# NUC1xx_registers register map
File version: 0.1
CPU: 
Registers are 32-bit, read-write, reset 0x0 unless marked. A register's access mark holds for its fields unless they carry their own. Offsets are from the block's base; [hi:lo] are bit positions; lines under a group give offsets from that group; 'fields as' and 'values as' point back to an identical list.

## CAN — Registers group
Base 0x40180000
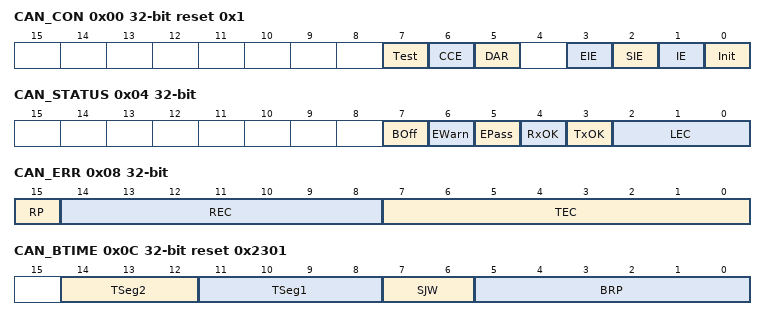
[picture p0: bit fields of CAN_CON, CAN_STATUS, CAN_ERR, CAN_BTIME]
0x00 CAN_CON reset 0x1 (reset mask 0xFFFFFFFE) — Control Register
  [7] Test — Test Mode Enable 1 = Test Mode. 0 = Normal Operation.
  [6] CCE — Configuration Change Enable 1 = Write access to the Bit Timing Register (CAN_BTIME & CAN_BRP) allowed. (while Init bit =1). 0 = No write access to the Bit Timing Register.
  [5] DAR — Disable Automatic Re-transmission 1 = Automatic Retransmission disabled. 0 = Automatic Retransmission of disturbed messages enabled.
  [3] EIE — Error Interrupt Enable 1 = Enabled - A change in the bits BOff or EWarn in the Status Register will generate an interrupt. 0 = Disabled - No Error Status Interrupt will be generated.
  [2] SIE — Status Change Interrupt Enable 1 = Enabled - An interrupt will be generated when a message transfer is successfully completed or a CAN bus error is detected. 0 = Disabled - No Status Change Interrupt will be generated.
  [1] IE — Module Interrupt Enable 1 = Enabled. 0 = Disabled.
  [0] Init — Init Initialization 1 = Initialization is started. 0 = Normal Operation.
0x04 CAN_STATUS — Status Register
  [7] BOff — Busoff Status (Read Only) 1 = The CAN module is in busoff state. 0 = The CAN module is not in busoff state.
  [6] EWarn — Error Warning Status (Read Only) 1 = At least one of the error counters in the EML has reached the error warning limit of 96. 0 = Both error counters are below the error warning limit of 96.
  [5] EPass — Error Passive (Read Only) 1 = The CAN Core is in the error passive state as defined in the CAN Specification. 0 = The CAN Core is error active.
  [4] RxOK — Received a Message Successfully 1 = A message has been successfully received since this bit was last reset by the CPU (independent of the result of acceptance filtering). 0 = No message has been successfully received since this bit was last reset by the CPU. This bit is never reset by the CAN Core.
  [3] TxOK — Transmitted a Message Successfully 1 = Since this bit was last reset by the CPU, a message has been successfully (error free and acknowledged by at least one other node) transmitted. 0 = Since this bit was reset by the CPU, no message has been successfully transmitted. This bit is never reset by the CAN Core.
  [2:0] LEC — Last Error Code (Type of the last error to occur on the CAN bus) The LEC field holds a code, which indicates the type of the last error to occur on the CAN bus. This field will be cleared to '0' when a message has been transferred (reception or transmission) without error. The unused code '7' may be written by the CPU to check for updates. Table 5-17 describes the error codes.
0x08 CAN_ERR ro — Error Counter
  [15] RP — Receive Error Passive 1 = The Receive Error Counter has reached the error passive level as defined in the CAN Specification. 0 = The Receive Error Counter is below the error passive level.
  [14:8] REC — Receive Error Counter Actual state of the Receive Error Counter. Values between 0 and 127.
  [7:0] TEC — Transmit Error Counter Actual state of the Transmit Error Counter. Values between 0 and 255.
0x0C CAN_BTIME reset 0x2301 (reset mask 0xFFFFDCFE) — Bit Timing Register
  [14:12] TSeg2 — Time Segment After sample Point 0x0-0x7: Valid values for TSeg2 are [0 ... 7]. The actual interpretation by the hardware of this value is such that one more than the value programmed here is used.
  [11:8] TSeg1 — Time Segment before the sample Point Minus Sync_seg 0x01-0x0F: valid values for TSeg1 are [1 ... 15]. The actual interpretation by the hardware of this value is such that one more than the value programmed is used.
  [7:6] SJW — (Re)Synchronization Jump Width 0x0-0x3: Valid programmed values are [0 ... 3]. The actual interpretation by the hardware of this value is such that one more than the value programmed here is used.
  [5:0] BRP — Baud Rate Prescaler 0x01-0x3F: The value by which the oscillator frequency is divided for generating the bit time quanta. The bit time is built up from a multiple of this quanta. Valid values for the Baud Rate Prescaler are [0...63]. The actual interpretation by the hardware of this value is such that one more than the value programmed here is used.
0x10 CAN_IIDR ro — Interrupt Identifier Register
  [15:0] IntId — Interrupt Identifier (Indicates the source of the interrupt. Ref. Table 5-18) If several interrupts are pending, the CAN Interrupt Register will point to the pending interrupt with the highest priority, disregarding their chronological order. An interrupt remains pending until the application software has cleared it. If IntId is different from 0x0000 and IE is set, the IRQ interrupt signal to the EIC is active. The interrupt remains active until IntId is back to value 0x0000 (the cause of the interrupt is reset) or until IE is reset. The Status Interrupt has the highest priority. Among the message interrupts, the Message Object' s interrupt priority decreases with increasing message number. A message interrupt is cleared by clearing the Message Object's IntPnd bit. The Status Interrupt is cleared by reading the Status Register.
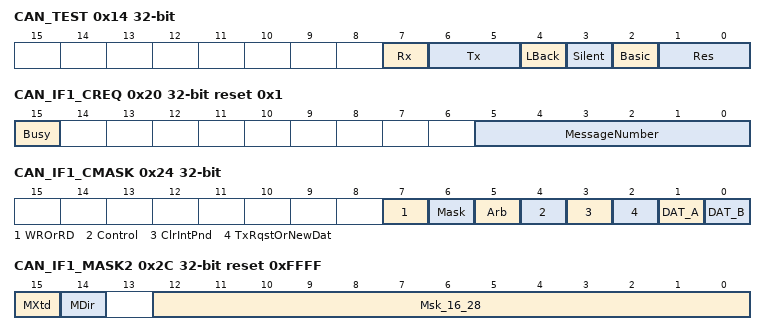
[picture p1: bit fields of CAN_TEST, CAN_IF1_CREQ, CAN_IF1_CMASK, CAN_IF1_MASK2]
0x14 CAN_TEST — Test Register
  [7] Rx — Monitors the actual value of CAN_RX Pin (Read Only) 1 = The CAN bus is recessive (CAN_RX = '1'). 0 = The CAN bus is dominant (CAN_RX = '0').
  [6:5] Tx — Tx[1:0]: Control of CAN_TX pin 00 = Reset value, CAN_TX is controlled by the CAN Core 01 = Sample Point can be monitored at CAN_TX pin 10 = CAN_TX pin drives a dominant ('0') value. 11 = CAN_TX pin drives a recessive ('1') value.
  [4] LBack — Loop Back Mode 1 = Loop Back Mode is enabled. 0 = Loop Back Mode is disabled.
  [3] Silent — Silent Mode 1 = The module is in Silent Mode. 0 = Normal operation.
  [2] Basic — Basic Mode 1= IF1 Registers used as Tx Buffer, IF2 Registers used as Rx Buffer. 0 = Basic Mode disabled.
  [1:0] Res — Reserved There are reserved bits. These bits are always read as '0' and must always be written with '0'.
0x18 CAN_BRPE — BRP Extension Register
  [3:0] BRPE — BRPE: Baud Rate Prescaler Extension 0x00-0x0F: By programming BRPE, the Baud Rate Prescaler can be extended to values up to 1023. The actual interpretation by the hardware is that one more than the value programmed by BRPE (MSBs) and BTIME (LSBs) is used.
0x20 CAN_IF1_CREQ reset 0x1 (reset mask 0xFFFFFFFE) — IF1 Command Request Register
  [15] Busy — Busy Flag 1 = Writing to the IF1 Command Request Register is in progress. This bit can only be read by the software. 0 = Read/write action has finished.
  [5:0] MessageNumber — Message Number 0x01-0x20: Valid Message Number, the Message Object in the Message RAM is selected for data transfer. 0x00: Not a valid Message Number, interpreted as 0x20. 0x21-0x3F: Not a valid Message Number, interpreted as 0x01-0x1F.
0x24 CAN_IF1_CMASK — IF1 Command Mask Registers
  [7] WROrRD — Write / Read 1 = Write: Transfer data from the selected Message Buffer Registers to the Message Object addressed by the Command Request Register. 0 = Read: Transfer data from the Message Object addressed by the Command Request Register into the selected Message Buffer Registers.
  [6] Mask — Access Mask Bits Direction = Write 1 = Transfer Identifier Mask + MDir + MXtd to Message Object. 0: = Mask bits unchanged. Direction = Read 1 = Transfer Identifier Mask + MDir + MXtd to IF1 Message Buffer Register. 0 = Mask bits unchanged.
  [5] Arb — Access Arbitration Bits Direction = Write 1 = Transfer Identifier + Dir + Xtd + MsgVal to Message Object 0 = Arbitration bits unchanged. Direction = Read 1 = Transfer Identifier + Dir + Xtd + MsgVal to IF1 Message Buffer Register. 0 = Arbitration bits unchanged.
  [4] Control — Control Access Control Bits Direction = Write 1 = Transfer Control Bits to Message Object. 0 = Control Bits unchanged Direction = Read 1 = Transfer Control Bits to IF1 Message Buffer Register. 0 = Control Bits unchanged.
  [3] ClrIntPnd — Clear Interrupt Pending Bit Direction = Write When writing to a Message Object, this bit is ignored. Direction = Read 1 = Clear IntPnd bit in the Message Object. 0 = IntPnd bit remains unchanged.
  [2] TxRqstOrNewDat — Access Transmission Request Bit when Direction = Write 1 = Set TxRqst bit. 0 = TxRqst bit unchanged. Note: If a transmission is requested by programming bit TxRqst/NewDat in the IF1 Command Mask Register, bit TxRqst in the IF2 Message Control Register will be ignored. Access New Data Bit when Direction = Read 1 = Clear NewDat bit in the Message Object 0 = NewDat bit remains unchanged. Note : A read access to a Message Object can be combined with the reset of the control bits IntPnd and NewDat. The values of these bits transferred to the IF1 Message Control Register always reflect the status before resetting these bits.
  [1] DAT_A — Access Data Bytes [3:0] Direction = Write 1 = Transfer Data Bytes [3:0] to Message Object 0 = Data Bytes [3:0] unchanged. Direction = Read 1 = Transfer Data Bytes [3:0] to IF1 Message Buffer Register. 0 = Data Bytes [3:0] unchanged.
  [0] DAT_B — Access Data Bytes [7:4] Direction = Write 1 = Transfer Data Bytes [7:4] to Message Object. 0 = Data Bytes [7:4] unchanged. Direction = Read 1 = Transfer Data Bytes [7:4] to IF1 Message Buffer Register. 0 = Data Bytes [7:4] unchanged.
0x28 CAN_IF1_MASK1 reset 0xFFFF (reset mask 0xFFFF0000) — IF1 Mask 1 Register
  [15:0] Msk_0_15 — Identifier Mask 15-0 1 = The corresponding identifier bit is used for acceptance filtering. 0 = The corresponding bit in the identifier of the message object cannot inhibit the match in the acceptance filtering.
0x2C CAN_IF1_MASK2 reset 0xFFFF (reset mask 0xFFFF0000) — IF1 Mask 2 Register
  [15] MXtd — Mask Extended Identifier 1 = The extended identifier bit (IDE) is used for acceptance filtering. 0 = The extended identifier bit (IDE) has no effect on the acceptance filtering. Note: When 11-bit ("standard") Identifiers are used for a Message Object, the identifiers of received Data Frames are written into bits ID28 to ID18. For acceptance filtering, only these bits together with mask bits Msk28 to Msk18 are considered.
  [14] MDir — Mask Message Direction 1 = The message direction bit (Dir) is used for acceptance filtering. 0 = The message direction bit (Dir) has no effect on the acceptance filtering.
  [12:0] Msk_16_28 — Identifier Mask 28-16 1 = The corresponding identifier bit is used for acceptance filtering. 0 = The corresponding bit in the identifier of the message object cannot inhibit the match in the acceptance filtering.
0x30 CAN_IF1_ARB1 — IF1 Arbitration 1 Register
  [15:0] ID_0_15 — Message Identifier 15-0 ID28 - ID0, 29-bit Identifier ("Extended Frame"). ID28 - ID18, 11-bit Identifier ("Standard Frame")
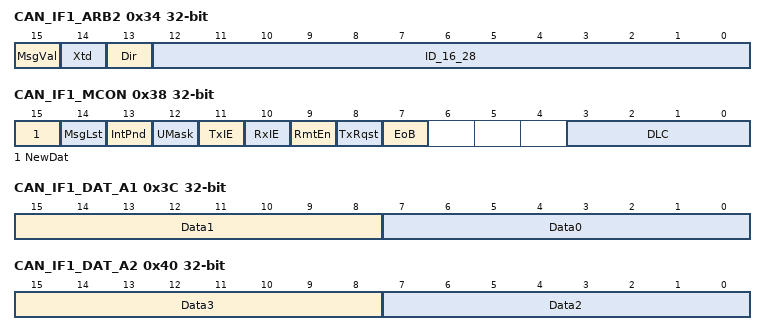
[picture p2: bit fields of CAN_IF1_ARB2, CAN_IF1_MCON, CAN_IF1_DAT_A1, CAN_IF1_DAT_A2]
0x34 CAN_IF1_ARB2 — IF1 Arbitration 2 Register
  [15] MsgVal — Message Valid 1 = The Message Object is configured and should be considered by the Message Handler. 0 = The Message Object is ignored by the Message Handler. Note: The application software must reset the MsgVal bit of all unused Messages Objects during the initialization before it resets bit Init in the CAN Control Register. This bit must also be reset before the identifier Id28-0, the control bits Xtd, Dir, or the Data Length Code DLC3-0 are modified, or if the Messages Object is no longer required.
  [14] Xtd — Extended Identifier 1 = The 29-bit ("extended") Identifier will be used for this Message Object. 0 = The 11-bit ("standard") Identifier will be used for this Message Object.
  [13] Dir — Message Direction 1 = Direction is transmit On TxRqst, the respective Message Object is transmitted as a Data Frame. On reception of a Remote Frame with matching identifier, the TxRqst bit of this Message Object is set (if RmtEn = one). 0 = Direction is receive On TxRqst, a Remote Frame with the identifier of this Message Object is transmitted. On reception of a Data Frame with matching identifier, that message is stored in this Message Object.
  [12:0] ID_16_28 — Message Identifier 28-16 ID28 - ID0, 29-bit Identifier ("Extended Frame"). ID28 - ID18, 11-bit Identifier ("Standard Frame")
0x38 CAN_IF1_MCON — IF1 Message Control Registers
  [15] NewDat — New Data 1 = The Message Handler or the application software has written new data into the data portion of this Message Object. 0 = No new data has been written into the data portion of this Message Object by the Message Handler since last time this flag was cleared by the application software.
  [14] MsgLst — Message Lost (only valid for Message Objects with direction = receive) 1 = The Message Handler stored a new message into this object when NewDat was still set, the CPU has lost a message. 0 = No message lost since last time this bit was reset by the CPU.
  [13] IntPnd — Interrupt Pending 1 = This message object is the source of an interrupt. The Interrupt Identifier in the Interrupt Register will point to this message object if there is no other interrupt source with higher priority. 0 = This message object is not the source of an interrupt.
  [12] UMask — Use Acceptance Mask 1 = Use Mask (Msk28-0, MXtd, and MDir) for acceptance filtering. 0 = Mask ignored. Note: If the UMask bit is set to one, the Message Object's mask bits have to be programmed during initialization of the Message Object before MsgVal is set to one.
  [11] TxIE — Transmit Interrupt Enable 1 = IntPnd will be set after a successful transmission of a frame. 0 = IntPnd will be left unchanged after the successful transmission of a frame.
  [10] RxIE — Receive Interrupt Enable 1 = IntPnd will be set after a successful reception of a frame. 0 = IntPnd will be left unchanged after a successful reception of a frame.
  [9] RmtEn — Remote Enable 1 = At the reception of a Remote Frame, TxRqst is set. 0 = At the reception of a Remote Frame, TxRqst is left unchanged.
  [8] TxRqst — Transmit Request 1 = The transmission of this Message Object is requested and is not yet done. 0 = This Message Object is not waiting for transmission.
  [7] EoB — End of Buffer 1 = Single Message Object or last Message Object of a FIFO Buffer. 0 = Message Object belongs to a FIFO Buffer and is not the last Message Object of that FIFO Buffer. Note: This bit is used to concatenate two or more Message Objects (up to 32) to build a FIFO Buffer. For single Message Objects (not belonging to a FIFO Buffer), this bit must always be set to one.
  [3:0] DLC — Data Length Code 0-8: Data Frame has 0-8 data bytes. 9-15: Data Frame has 8 data bytes Note: The Data Length Code of a Message Object must be defined the same as in all the corresponding objects with the same identifier at other nodes. When the Message Handler stores a data frame, it will write the DLC to the value given by the received message. Data 0: 1st data byte of a CAN Data Frame Data 1: 2nd data byte of a CAN Data Frame Data 2: 3rd data byte of a CAN Data Frame Data 3: 4th data byte of a CAN Data Frame Data 4: 5th data byte of a CAN Data Frame Data 5: 6th data byte of a CAN Data Frame Data 6: 7th data byte of a CAN Data Frame Data 7 : 8th data byte of a CAN Data Frame Note: The Data 0 Byte is the first data byte shifted into the shift register of the CAN Core during a reception while the Data 7 byte is the last. When the Message Handler stores a Data Frame, it will write all the eight data bytes into a Message Object. If the Data Length Code is less than 8, the remaining bytes of the Message Object will be overwritten by unspecified values.
0x3C CAN_IF1_DAT_A1 — IF1 Data A1 Registers
  [15:8] Data1 — Data byte 1 2nd data byte of a CAN Data Frame
  [7:0] Data0 — Data byte 0 1st data byte of a CAN Data Frame
0x40 CAN_IF1_DAT_A2 — IF1 Data A2 Registers
  [15:8] Data3 — Data byte 3 2nd data byte of a CAN Data Frame
  [7:0] Data2 — Data byte 2 1st data byte of a CAN Data Frame
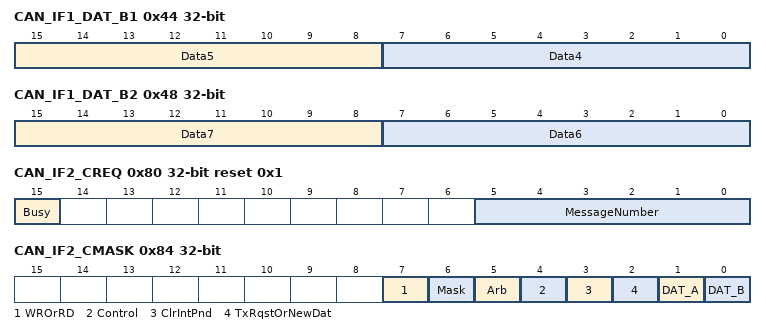
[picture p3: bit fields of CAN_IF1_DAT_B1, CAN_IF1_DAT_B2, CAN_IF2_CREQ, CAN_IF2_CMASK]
0x44 CAN_IF1_DAT_B1 — IF1 Data B1 Registers
  [15:8] Data5 — Data byte 5 2nd data byte of a CAN Data Frame
  [7:0] Data4 — Data byte 4 1st data byte of a CAN Data Frame
0x48 CAN_IF1_DAT_B2 — IF1 Data B2 Registers
  [15:8] Data7 — Data byte 7 2nd data byte of a CAN Data Frame
  [7:0] Data6 — Data byte 6 1st data byte of a CAN Data Frame
0x80 CAN_IF2_CREQ reset 0x1 (reset mask 0xFFFFFFFE) — IF2 Command Request Register
  [15] Busy — Busy Flag 1 = Writing to the IF2 Command Request Register is in progress. This bit can only be read by the software. 0 = Read/write action has finished.
  [5:0] MessageNumber — Message Number 0x01-0x20: Valid Message Number, the Message Object in the Message RAM is selected for data transfer. 0x00: Not a valid Message Number, interpreted as 0x20. 0x21-0x3F: Not a valid Message Number, interpreted as 0x01-0x1F.
0x84 CAN_IF2_CMASK — IF2 Command Mask Register
  [7] WROrRD — Write / Read 1 = Write: Transfer data from the selected Message Buffer Registers to the Message Object addressed by the Command Request Register. 0 = Read: Transfer data from the Message Object addressed by the Command Request Register into the selected Message Buffer Registers.
  [6] Mask — Access Mask Bits Direction = Write 1 = Transfer Identifier Mask + MDir + MXtd to Message Object. 0: = Mask bits unchanged. Direction = Read 1 = Transfer Identifier Mask + MDir + MXtd to IF2 Message Buffer Register. 0 = Mask bits unchanged.
  [5] Arb — Access Arbitration Bits Direction = Write 1 = Transfer Identifier + Dir + Xtd + MsgVal to Message Object 0 = Arbitration bits unchanged. Direction = Read 1 = Transfer Identifier + Dir + Xtd + MsgVal to IF2 Message Buffer Register. 0 = Arbitration bits unchanged.
  [4] Control — Control Access Control Bits Direction = Write 1 = Transfer Control Bits to Message Object. 0 = Control Bits unchanged Direction = Read 1 = Transfer Control Bits to IF2 Message Buffer Register. 0 = Control Bits unchanged.
  [3] ClrIntPnd — Clear Interrupt Pending Bit Direction = Write When writing to a Message Object, this bit is ignored. Direction = Read 1 = Clear IntPnd bit in the Message Object. 0 = IntPnd bit remains unchanged.
  [2] TxRqstOrNewDat — Access Transmission Request Bit when Direction = Write 1 = Set TxRqst bit. 0 = TxRqst bit unchanged. Note: If a transmission is requested by programming bit TxRqst/NewDat in the IF2 Command Mask Register, bit TxRqst in the IF2 Message Control Register will be ignored. Access New Data Bit when Direction = Read 1 = Clear NewDat bit in the Message Object 0 = NewDat bit remains unchanged. Note : A read access to a Message Object can be combined with the reset of the control bits IntPnd and NewDat. The values of these bits transferred to the IF2 Message Control Register always reflect the status before resetting these bits.
  [1] DAT_A — Access Data Bytes [3:0] Direction = Write 1 = Transfer Data Bytes [3:0] to Message Object 0 = Data Bytes [3:0] unchanged. Direction = Read 1 = Transfer Data Bytes [3:0] to IF2 Message Buffer Register. 0 = Data Bytes [3:0] unchanged.
  [0] DAT_B — Access Data Bytes [7:4] Direction = Write 1 = Transfer Data Bytes [7:4] to Message Object. 0 = Data Bytes [7:4] unchanged. Direction = Read 1 = Transfer Data Bytes [7:4] to IF2 Message Buffer Register. 0 = Data Bytes [7:4] unchanged.
0x88 CAN_IF2_MASK1 reset 0xFFFF (reset mask 0xFFFF0000) — IF2 Mask 1 Registers
  fields as CAN_IF1_MASK1
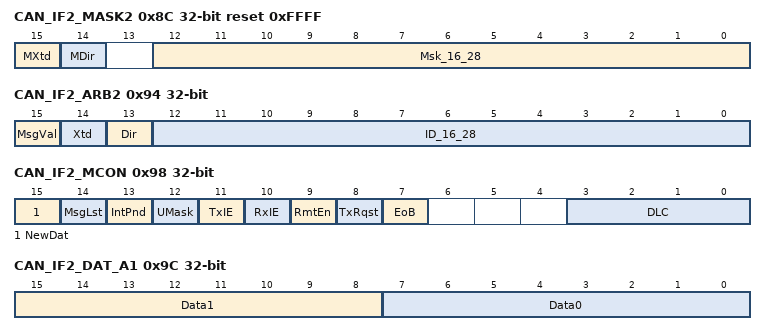
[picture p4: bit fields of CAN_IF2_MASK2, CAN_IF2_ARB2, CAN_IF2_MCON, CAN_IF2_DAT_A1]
0x8C CAN_IF2_MASK2 reset 0xFFFF (reset mask 0xFFFF0000) — IF2 Mask 2 Registers
  fields as CAN_IF1_MASK2
0x90 CAN_IF2_ARB1 — IF2 Arbitration 1 Register
  fields as CAN_IF1_ARB1
0x94 CAN_IF2_ARB2 — IF2 Arbitration 2 Register
  fields as CAN_IF1_ARB2
0x98 CAN_IF2_MCON — IF2 Message Control Register
  fields as CAN_IF1_MCON
0x9C CAN_IF2_DAT_A1 — IF2 Data A1 Registers
  fields as CAN_IF1_DAT_A1
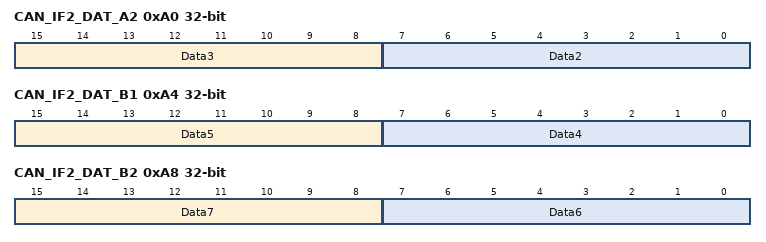
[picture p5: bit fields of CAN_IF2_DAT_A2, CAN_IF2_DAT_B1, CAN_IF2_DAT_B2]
0xA0 CAN_IF2_DAT_A2 — IF2 Data A2 Registers
  fields as CAN_IF1_DAT_A2
0xA4 CAN_IF2_DAT_B1 — IF2 Data B1 Registers
  fields as CAN_IF1_DAT_B1
0xA8 CAN_IF2_DAT_B2 — IF2 Data B2 Registers
  fields as CAN_IF1_DAT_B2
0x100 CAN_TXREQ1 ro — Transmission Request Registers 1
  [15:0] TxRqst1_16 — Transmission Request Bits 1-16 (of all Message Objects) 1 = The transmission of this Message Object is requested and is not yet done. 0 = This Message Object is not waiting for transmission. These bits are read only.
0x104 CAN_TXREQ2 ro — Transmission Request Register 2
  [15:0] TxRqst17_32 — Transmission Request Bits 17-32 (of all Message Objects) 1 = The transmission of this Message Object is requested and is not yet done. 0 = This Message Object is not waiting for transmission. These bits are read only.
0x120 CAN_NDAT1 ro — New Data Register 1
  [15:0] NewData1_16 — New Data Bits 1-16 (of all Message Objects) 1 = The Message Handler or the application software has written new data into the data portion of this Message Object. 0 = No new data has been written into the data portion of this Message Object by the Message Handler since the last time this flag was cleared by the application software.
0x124 CAN_NDAT2 ro — New Data Register 2
  [15:0] NewData17_32 — New Data Bits 17-32 (of all Message Objects) 1 = The Message Handler or the application software has written new data into the data portion of this Message Object. 0 = No new data has been written into the data portion of this Message Object by the Message Handler since the last time this flag was cleared by the application software.
0x140 CAN_IPND1 ro — Interrupt Pending Register 1
  [15:0] IntPnd1_16 — Interrupt Pending Bits 1-16 (of all Message Objects) 1 = This message object is the source of an interrupt. 0 = This message object is not the source of an interrupt.
0x144 CAN_IPND2 ro — Interrupt Pending Register 2
  [15:0] IntPnd17_32 — Interrupt Pending Bits 17-32 (of all Message Objects) 1 = This message object is the source of an interrupt. 0 = This message object is not the source of an interrupt.
0x160 CAN_MVLD1 ro — Message Valid Register 1
  [15:0] MsgVal1_16 — Message Valid Bits 1-16 (of all Message Objects) (Read Only) 1 = This Message Object is configured and should be considered by the Message Handler. 0 = This Message Object is ignored by the Message Handler. Ex. CAN_MVLD1[0] means Message object No.1 is valid or not. If CAN_MVLD1[0] is set, message object No.1 is configured.
0x164 CAN_MVLD2 ro — Message Valid Register 2
  [15:0] MsgVal17_32 — Message Valid Bits 17-32 (of all Message Objects) (Read Only) 1 = This Message Object is configured and should be considered by the Message Handler. 0 = This Message Object is ignored by the Message Handler. Ex. CAN_MVLD1[0] means Message object No.1 is valid or not. If CAN_MVLD1[0] is set, message object No.1 is configured.
0x168 CAN_WU_EN — Wake Up Function Enable
  [0] WAKUP_EN — Wake Up Enable 1 = The wake-up function is enable. 0 = The wake-up function is disable. Note: User can wake-up system when there is a falling edge in the CAN_Rx pin..
0x16C CAN_WU_STATUS — Wake Up Function Status
  [0] WAKUP_STS — Wake Up Status 1 = Wake-up event is occurred. 0 = No wake-up event is occurred. Note: The bit can be written '0' to clear.
